# VPAC0_COMMON_0_IVPAC_TOP_0_CFG_SLV_PAR_VPAC_VISS0_S_VBUSP_VISS_FCP_FCC_VBUSP_FLEXCC_Y8R8 register map
Vendor: Texas Instruments
Peripheral module from a debugger description file (folder am62A).
Registers are 32-bit, read-write, reset 0x0 unless marked. A register's access mark holds for its fields unless they carry their own. Offsets are as the file gives them; lines under a group give offsets from that group; [hi:lo] are bit positions; {n}, {i} and the like mark numbered series; 'fields as' and 'values as' point back to an identical list; <NAME> marks a mode.

## VPAC0_COMMON_0_IVPAC_TOP_0_CFG_SLV_PAR_VPAC_VISS0_S_VBUSP_VISS_FCP_FCC_VBUSP_FLEXCC_Y8R8
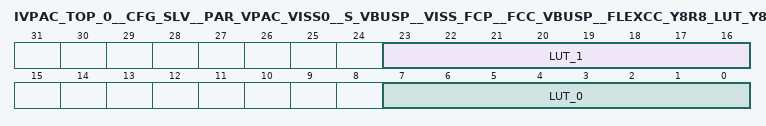
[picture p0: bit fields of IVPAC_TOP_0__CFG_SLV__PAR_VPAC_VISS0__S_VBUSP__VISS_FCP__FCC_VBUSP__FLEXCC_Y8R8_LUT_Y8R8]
0x00 IVPAC_TOP_0__CFG_SLV__PAR_VPAC_VISS0__S_VBUSP__VISS_FCP__FCC_VBUSP__FLEXCC_Y8R8_LUT_Y8R8 — Memory for 12to8 LUT
  [23:16] LUT_1 — Bank-1
  [7:0] LUT_0 — Bank-0
